# OPQ_UPSTREAM_4LANE register map
File version: 26.4.14.0428
Ordered priority queue runtime CSR aperture for the MuSiP SWB integration.
Registers are 32-bit, read-only, reset 0x0 unless marked. A register's access mark holds for its fields unless they carry their own. Offsets are from the block's base; lines under a group give offsets from that group; [hi:lo] are bit positions; {n}, {i} and the like mark numbered series; 'fields as' and 'values as' point back to an identical list; <NAME> marks a mode.

## Memory map
0x00000000 OPQ size 0x400 — Ordered priority queue CSR window accessed through the Platform Designer JTAG Avalon master.

## OPQ — Ordered priority queue CSR window accessed through the Platform Designer JTAG Avalon master.
Base 0x00000000
0x00 UID reset 0x4F50514D — Immutable Mu3e IP identifier. Default ASCII "OPQM".
  [31:0] VALUE — ASCII "OPQM" packed as 0x4F50514D.
0x04 META rw reset 0x1A04D1AC — Write PAGE_SEL[1:0], then read selected identity payload: 0=VERSION, 1=VERSION_DATE, 2=VERSION_GIT, 3=INSTANCE_ID.
  [1:0] PAGE_SEL — Selects the META payload page on write.
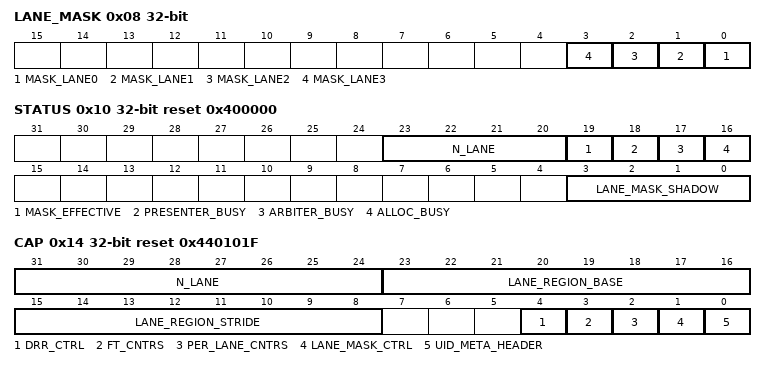
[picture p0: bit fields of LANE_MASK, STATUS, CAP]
0x08 LANE_MASK rw — Runtime packet-boundary lane mask. A set bit disables new packets on that lane after the current packet drains.
  [n] MASK_LANE{n} (n=0..3) — Mask ingress lane {n} at packet boundaries when set.
0x0C CTRL wo — Control pulses. Write CLEAR_COUNTERS=1 to clear all software-visible counters.
  [0] CLEAR_COUNTERS — Write-one pulse clears per-lane and frame-table counters.
0x10 STATUS reset 0x400000 — Aggregated lane-mask, busy, presenter, and effective-mask status.
  [23:20] N_LANE — Instantiated lane count.
  [19] MASK_EFFECTIVE — At least one lane is currently blocked by the packet-boundary mask.
  [18] PRESENTER_BUSY — Egress presenter is currently valid.
  [17] ARBITER_BUSY — Page-RAM write-port arbiter is active.
  [16] ALLOC_BUSY — Page allocator is active.
  [3:0] LANE_MASK_SHADOW — Current software-programmed lane mask.
0x14 CAP reset 0x440101F — Capability summary and per-lane CSR-region geometry.
  [31:24] N_LANE — Instantiated lane count.
  [23:16] LANE_REGION_BASE — Base word address of the per-lane CSR region.
  [15:8] LANE_REGION_STRIDE — Per-lane CSR region stride in 32-bit words.
  [4] DRR_CTRL — Per-lane DRR allowance programming and live observability are implemented.
  [3] FT_CNTRS — Frame-table write/read/drop counters are implemented.
  [2] PER_LANE_CNTRS — Per-lane write/read/drop and credit counters are implemented.
  [1] LANE_MASK_CTRL — Packet-boundary lane mask control is implemented.
  [0] UID_META_HEADER — Common Mu3e UID + META identity header is implemented.
0x20 FT_WR_HDR — Headers committed into frame-table ownership.
0x24 FT_WR_SHD — Subheaders committed into frame-table ownership.
0x28 FT_WR_HIT — Hits committed into frame-table ownership.
0x2C FT_RD_HDR — Headers retired through the egress presenter.
0x30 FT_RD_SHD — Subheaders retired through the egress presenter.
0x34 FT_RD_HIT — Hits retired through the egress presenter.
0x38 FT_DROP_HDR — Headers dropped by frame-table overwrite or overwrite recovery.
0x3C FT_DROP_SHD — Subheaders dropped by frame-table overwrite or overwrite recovery.
0x40 FT_DROP_HIT — Hits dropped by frame-table overwrite or overwrite recovery.
{0x100+0x40*i} LANE{i}_WR_HDR_CNT (i=0..3) — Per-lane header tickets accepted from ingress parsing.
{0x104+0x40*i} LANE{i}_WR_SHD_CNT (i=0..3) — Per-lane subheader tickets accepted from ingress parsing.
{0x108+0x40*i} LANE{i}_WR_HIT_CNT (i=0..3) — Per-lane hit words written into the lane FIFO.
{0x10C+0x40*i} LANE{i}_RD_HDR_CNT (i=0..3) — Per-lane header tickets consumed by the page allocator.
{0x110+0x40*i} LANE{i}_RD_SHD_CNT (i=0..3) — Per-lane subheaders accepted into the merged page stream.
{0x114+0x40*i} LANE{i}_RD_HIT_CNT (i=0..3) — Per-lane hits accepted into the merged page stream.
{0x118+0x40*i} LANE{i}_DROP_HDR_CNT (i=0..3) — Per-lane dropped headers before frame-table ownership.
{0x11C+0x40*i} LANE{i}_DROP_SHD_CNT (i=0..3) — Per-lane dropped subheaders before frame-table ownership.
{0x120+0x40*i} LANE{i}_DROP_HIT_CNT (i=0..3) — Per-lane dropped hits before frame-table ownership.
{0x124+0x40*i} LANE{i}_LANE_CREDIT (i=0..3) — Current lane-FIFO free-credit counter.
{0x128+0x40*i} LANE{i}_TICKET_CREDIT (i=0..3) — Current ticket-FIFO free-credit counter.
{0x12C+0x40*i} LANE{i}_DRR_ALLOWANCE rw reset 0x100 (i=0..3) — Per-lane DRR refill allowance. Writes reseed the live quantum.
  [9:0] ALLOWANCE — DRR refill allowance in page words.
{0x130+0x40*i} LANE{i}_DRR_QUANTUM (i=0..3) — Current live DRR quantum or deficit budget.
{0x134+0x40*i} LANE{i}_DRR_GRANT_CNT (i=0..3) — Number of block-level arbiter lock windows granted to this lane.
{0x138+0x40*i} LANE{i}_DRR_BEAT_CNT (i=0..3) — Number of page-RAM data beats served from this lane.
{0x13C+0x40*i} LANE{i}_DRR_DEFER_CNT (i=0..3) — Number of defer rounds where this lane requested service but could not cover the whole block.
